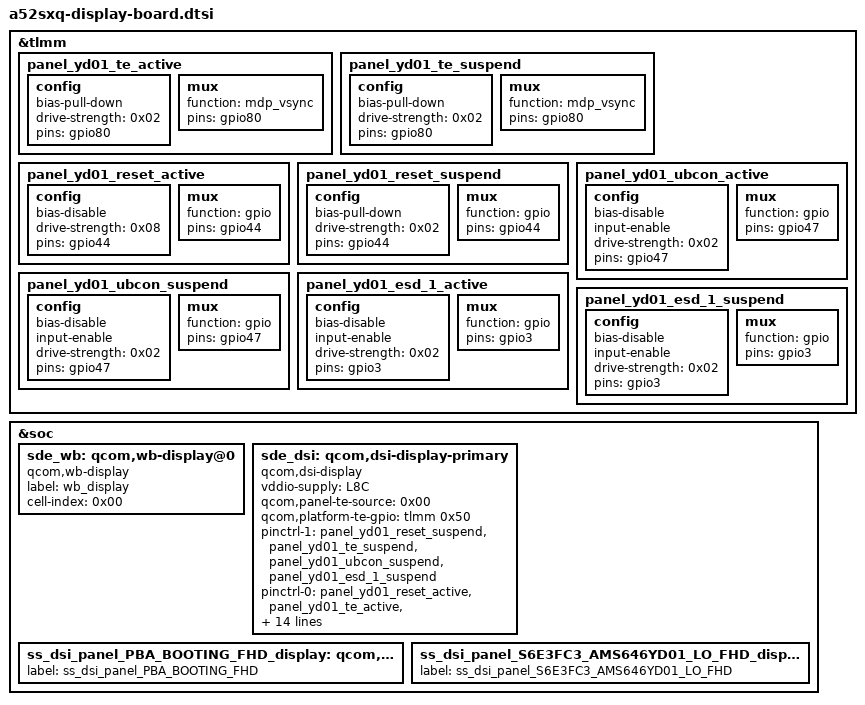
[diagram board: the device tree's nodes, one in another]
// SPDX-License-Identifier: GPL-2.0-only
/*
 * A52s display board wiring: pin states, DSI display node, Samsung display-name nodes.
 * GENERATED by tools/gen-dts.py from downstream-dt/a52sxq-r02.dts (the merged tree the
 * phone boots: yupik.dtb + overlay a52sxq_kor_single_w00_r02, used by hardware revisions
 * 2 and later, so 3 and 4 too). Values are byte-for-byte the phone's; only phandles were
 * turned into labels. Do not edit by hand; edit the generator.
 */

&tlmm {
	panel_yd01_te_active: panel_yd01_te_active {

		config {
			bias-pull-down;
			drive-strength = <0x02>;
			pins = "gpio80";
		};

		mux {
			function = "mdp_vsync";
			pins = "gpio80";
		};
	};

	panel_yd01_te_suspend: panel_yd01_te_suspend {

		config {
			bias-pull-down;
			drive-strength = <0x02>;
			pins = "gpio80";
		};

		mux {
			function = "mdp_vsync";
			pins = "gpio80";
		};
	};

	panel_yd01_reset_active: panel_yd01_reset_active {

		config {
			bias-disable;
			drive-strength = <0x08>;
			pins = "gpio44";
		};

		mux {
			function = "gpio";
			pins = "gpio44";
		};
	};

	panel_yd01_reset_suspend: panel_yd01_reset_suspend {

		config {
			bias-pull-down;
			drive-strength = <0x02>;
			pins = "gpio44";
		};

		mux {
			function = "gpio";
			pins = "gpio44";
		};
	};

	panel_yd01_ubcon_active: panel_yd01_ubcon_active {

		config {
			bias-disable;
			input-enable;
			drive-strength = <0x02>;
			pins = "gpio47";
		};

		mux {
			function = "gpio";
			pins = "gpio47";
		};
	};

	panel_yd01_ubcon_suspend: panel_yd01_ubcon_suspend {

		config {
			bias-disable;
			input-enable;
			drive-strength = <0x02>;
			pins = "gpio47";
		};

		mux {
			function = "gpio";
			pins = "gpio47";
		};
	};

	panel_yd01_esd_1_active: panel_yd01_esd_1_active {

		config {
			bias-disable;
			input-enable;
			drive-strength = <0x02>;
			pins = "gpio3";
		};

		mux {
			function = "gpio";
			pins = "gpio3";
		};
	};

	panel_yd01_esd_1_suspend: panel_yd01_esd_1_suspend {

		config {
			bias-disable;
			input-enable;
			drive-strength = <0x02>;
			pins = "gpio3";
		};

		mux {
			function = "gpio";
			pins = "gpio3";
		};
	};
};

&soc {
	sde_wb: qcom,wb-display@0 {
		label = "wb_display";
		cell-index = <0x00>;
		compatible = "qcom,wb-display";
	};

	sde_dsi: qcom,dsi-display-primary {
		vddio-supply = <&L8C>;
		qcom,panel-te-source = <0x00>;
		qcom,platform-te-gpio = <&tlmm 0x50 0x0>;
		pinctrl-1 = <&panel_yd01_reset_suspend &panel_yd01_te_suspend &panel_yd01_ubcon_suspend &panel_yd01_esd_1_suspend>;
		pinctrl-0 = <&panel_yd01_reset_active &panel_yd01_te_active &panel_yd01_ubcon_active &panel_yd01_esd_1_active>;
		pinctrl-names = "panel_active", "panel_suspend";
		clock-names = "mux_byte_clk0", "mux_pixel_clk0", "cphy_byte_clk0", "cphy_pixel_clk0", "src_byte_clk0", "src_pixel_clk0", "shadow_byte_clk0", "shadow_pixel_clk0", "shadow_cphybyte_clk0", "shadow_cphypixel_clk0", "mdp_core_clk";
		clocks = <&mdss_dsi_phy0 0x6>, <&mdss_dsi_phy0 0x9>, <&mdss_dsi_phy0 0x12>, <&mdss_dsi_phy0 0x15>, <&mdss_dsi_phy0 0x3>, <&mdss_dsi_phy0 0x8>, <&mdss_dsi_phy0 0xd>, <&mdss_dsi_phy0 0x11>, <&mdss_dsi_phy0 0x16>, <&mdss_dsi_phy0 0x19>, <&dispcc DISP_CC_MDSS_MDP_CLK>;
		qcom,dsi-default-panel = <&ss_dsi_panel_S6E3FC3_AMS646YD01_LO_FHD>;
		qcom,mdp = <&mdss_mdp>;
		qcom,dsi-phy = <&mdss_dsi_phy0>;
		qcom,dsi-ctrl = <&mdss_dsi0>;
		label = "primary";
		compatible = "qcom,dsi-display";
	};

	ss_dsi_panel_PBA_BOOTING_FHD_display: qcom,dsi-display@0 {
		label = "ss_dsi_panel_PBA_BOOTING_FHD";
	};

	ss_dsi_panel_S6E3FC3_AMS646YD01_LO_FHD_display: qcom,dsi-display@1 {
		label = "ss_dsi_panel_S6E3FC3_AMS646YD01_LO_FHD";
	};
};
